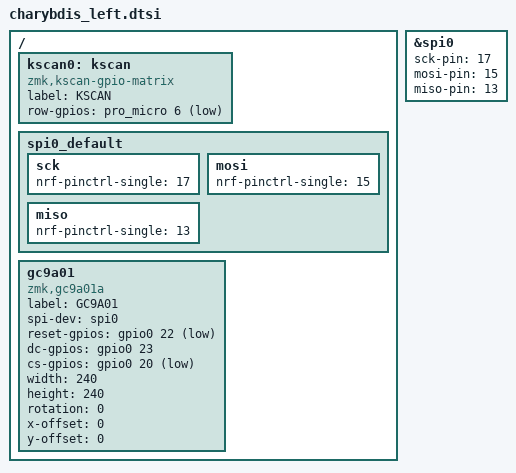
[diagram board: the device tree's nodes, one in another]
#include "charybdis.dtsi"                                                                                            
#include <dt-bindings/gpio/gpio.h>
#include <dt-bindings/pinctrl/nrf-pinctrl.h> 
/ {
	kscan0: kscan {
		compatible = "zmk,kscan-gpio-matrix";
		label = "KSCAN";
		row-gpios = <&pro_micro 6 (GPIO_ACTIVE_LOW | GPIO_PULL_UP)>;
	};
};
/ {
    /* SPI 引脚配置 */
    spi0_default: spi0_default {
        sck {
            nrf-pinctrl-single = <17>;
        };
        mosi {
            nrf-pinctrl-single = <15>;
        };
        miso {
            nrf-pinctrl-single = <13>;
        };
    };

    /* GC9A01 显示屏定义 */
    gc9a01: gc9a01 {
        compatible = "zmk,gc9a01a";
        label = "GC9A01";
        spi-dev = <&spi0>;
        reset-gpios = <&gpio0 22 (GPIO_ACTIVE_LOW)>;
        dc-gpios = <&gpio0 23 (GPIO_ACTIVE_HIGH)>;
        cs-gpios = <&gpio0 20 (GPIO_ACTIVE_LOW)>;
        width = <240>;
        height = <240>;
        rotation = <0>;
        x-offset = <0>;
        y-offset = <0>;
    };
};

&spi0 {
    status = "okay";
    
    /* 旧式引脚配置 (必需) */
    sck-pin = <17>;    /* P0.17 */
    mosi-pin = <15>;   /* P0.15 */
    miso-pin = <13>;   /* P0.13 */
    
    /* pinctrl 配置 (可选，如果支持) */
    /* pinctrl-0 = <&spi0_default>; */
    /* pinctrl-names = "default"; */
};

                                                                               
